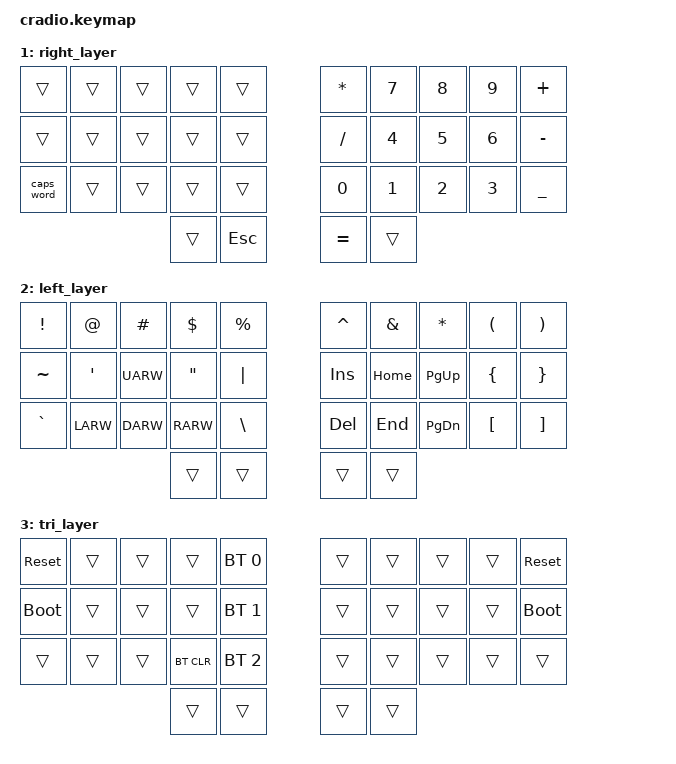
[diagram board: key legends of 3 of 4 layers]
// Copyright (c) 2022 The ZMK Contributors
// SPDX-License-Identifier: MIT

#include <behaviors.dtsi>
#include <dt-bindings/zmk/keys.h>
#include <dt-bindings/zmk/bt.h>

// Home row mods macro
#define HRML(k1,k2,k3,k4) &ht LSHFT k1  &ht LCTRL k2  &ht LALT k3  &ht LGUI k4
#define HRMR(k1,k2,k3,k4) &ht RGUI k1  &ht RALT k2  &ht RCTRL k3  &ht RSHFT k4

#define default_layer 0
#define right_layer 1
#define left_layer 2
#define tri_layer 3

// Combo Funct
#define COMBO(NAME, BINDINGS, LAYERS, KEYPOS) \
    combo_##NAME { \
        timeout-ms = <50>; \
        bindings = <BINDINGS>; \
        key-positions = <KEYPOS>; \
        layers = <LAYERS>;  \
    };

/ {
    behaviors {
        ht: hold_tap {
            compatible = "zmk,behavior-hold-tap";
            #binding-cells = <2>;
            flavor = "tap-preferred";
            tapping-term-ms = <220>;
            quick-tap-ms = <150>;
            require-prior-idle-ms = <100>;
            bindings = <&kp>, <&kp>;
        };
    };
};

/{
   macros {
        theMacro: theMacro {
            label = "THEMACRO";
            compatible = "zmk,behavior-macro";
            #binding-cells = <0>;
            bindings
                = <&kp T &kp H &kp E>;
        };

        gitPush: gitPushMacro {
            label = "GITPUSHMACRO";
            compatible = "zmk,behavior-macro";
            #binding-cells = <0>;
            bindings
                = <&kp G &kp I &kp T &kp SPACE &kp P &kp U &kp S &kp H &kp ENTER>;
        };

        gitPull: gitPullMacro {
            label = "GITPULLMACRO";
            compatible = "zmk,behavior-macro";
            #binding-cells = <0>;
            bindings
                = <&kp G &kp I &kp T &kp SPACE &kp P &kp U &kp L &kp L &kp ENTER>;
        };

        gitAdd: gitAddMacro {
            label = "GITADDMACRO";
            compatible = "zmk,behavior-macro";
            #binding-cells = <0>;
            bindings
                = <&kp G &kp I &kp T &kp SPACE &kp A &kp D &kp D &kp SPACE &kp DOT &kp ENTER>;
        };

        gitCommit: gitCommitMacro {
            label = "GITCOMMITMACRO";
            compatible = "zmk,behavior-macro";
            #binding-cells = <0>;
            bindings
                = <&kp G &kp I &kp T &kp SPACE &kp C &kp O &kp M &kp M &kp I &kp T &kp SPACE &kp MINUS &kp M &kp SPACE &kp DQT>;
        };

        clear: clearMacro {
            label = "CLEARMACRO";
            compatible = "zmk,behavior-macro";
            #binding-cells = <0>;
            bindings
                = <&kp C &kp L &kp E &kp A &kp R &kp ENTER>;
        };
    };
};

/{
    conditional_layers {
        compatible = "zmk,conditional-layers";
        tri_layer {
            if-layers = <1 2>;
            then-layer = <3>;
        };
    };
};

/*
/{
    combos{
        compatible = "zmk,combos";
        COMBO(easyThe, &theMacro, 0 1, 3 4)
        COMBO(pushCombo, &gitPush, 0 1, 14 16)
        COMBO(commitCombo, &gitCommit, 0 1, 14 15)
        COMBO(pullCombo, &gitPull, 0 1, 2 14)
        COMBO(addCombo, &gitAdd, 0 1, 3 14)
        COMBO(clearCombo, &clear, 0 1, 31 32)
        COMBO(wordDeleteW, &kp DELETEW, 0 1, 30 31)
        COMBO(wordDelete, &kp DELETE, 0, 30 31)
    };
};
*/

        //╭──────────┬──────────┬──────────┬──────────┬──────────╮   ╭──────────┬──────────┬──────────┬──────────┬──────────╮
        //│    0     │    1     │    2     │     3    │   4      │   │     5    │   6      │     7    │     8    │    9     │
        //├──────────┼──────────┼──────────┼──────────┼──────────┤   ├──────────┼──────────┼──────────┼──────────┼──────────┤
        //│    10    │    11    │    12    │   13     │   14     │   │   15     │    16    │    17    │    18    │    19    │
        //├──────────┼──────────┼──────────┼──────────┼──────────┤   ├──────────┼──────────┼──────────┼──────────┼──────────┤
        //│     20   │    21    │   22     │   23     │     24   │   │    25    │    26    │   27     │    28    │   29     │
        //╰──────────┴──────────┴──────────┼──────────┼──────────┤   ├──────────┼──────────┼──────────┴──────────┴──────────╯
        //                                 |    30    |     31   |   |    32    |    33    |
        //                                 ╰──────────┴──────────╯   ╰──────────┴──────────╯

/{
    keymap {
        compatible = "zmk,keymap";
        default_layer {
            bindings = <
        //╭──────────┬──────────┬──────────┬──────────┬──────────╮   ╭──────────┬──────────┬──────────┬──────────┬──────────╮
        //│  Q       │  W       │  E       │  R       │  T       │   │  Y       │  U       │  I       │  O       │  P       │
            &kp Q      &kp W      &kp E      &kp R      &kp T          &kp Y      &kp U      &kp I      &kp O      &kp P
        //├──────────┼──────────┼──────────┼──────────┼──────────┤   ├──────────┼──────────┼──────────┼──────────┼──────────┤
        //│  A       │  S       │  D       │  F       │  G       │   │  H       │  J       │  K       │  L       │ ; :      │
            HRML(A,        S,         D,         F)     &kp G          &kp H      HRMR(J,        K,         L,        SEMI)
        //├──────────┼──────────┼──────────┼──────────┼──────────┤   ├──────────┼──────────┼──────────┼──────────┼──────────┤
        //│  Z       │  X       │  C       │  V       │  B       │   │  N       │  M       │ , <      │ . >      │ / ?      │
            &kp Z      &kp X      &kp C      &kp V      &kp B          &kp N      &kp M      &kp COMMA  &kp DOT    &kp FSLH
        //╰──────────┴──────────┴──────────┼──────────┼──────────┤   ├──────────┼──────────┼──────────┴──────────┴──────────╯
                                            &lt 2 TAB   &kp SPACE     &kp ENTER  &lt 1 BSPC
        //                                 ╰──────────┴──────────╯   ╰──────────┴──────────╯
            >;
        };

        /*
        default_layer {
            bindings = <
        //╭──────────┬──────────┬──────────┬──────────┬──────────╮   ╭──────────┬──────────┬──────────┬──────────┬──────────╮
        //│  Q       │  W       │  E       │  R       │  T       │   │  Y       │  U       │  I       │  O       │  P       │
            &kp Q      &kp W      &kp E      &kp R      &kp T          &kp Y      &kp U      &kp I      &kp O      &kp P
        //├──────────┼──────────┼──────────┼──────────┼──────────┤   ├──────────┼──────────┼──────────┼──────────┼──────────┤
        //│  A       │  S       │  D       │  F       │  G       │   │  H       │  J       │  K       │  L       │ ; :      │
            HRML(A,        S,         D,         F)     &kp G          &kp H      HRMR(J,        K,         L,        SEMI)
        //├──────────┼──────────┼──────────┼──────────┼──────────┤   ├──────────┼──────────┼──────────┼──────────┼──────────┤
        //│  Z       │  X       │  C       │  V       │  B       │   │  N       │  M       │ , <      │ . >      │ / ?      │
            &kp Z      &kp X      &kp C      &kp V      &kp B          &kp N      &kp M      &kp COMMA  &kp DOT    &kp FSLH
        //╰──────────┴──────────┴──────────┼──────────┼──────────┤   ├──────────┼──────────┼──────────┴──────────┴──────────╯
                                            &lt 2 TAB   &kp SPACE     &kp ENTER  &lt 1 BSPC
        //                                 ╰──────────┴──────────╯   ╰──────────┴──────────╯
            >;
        };
        */

        right_layer {
            bindings = <
        //╭──────────┬──────────┬──────────┬──────────┬──────────╮   ╭──────────┬──────────┬──────────┬──────────┬──────────╮
        //│          │          │          │          │          │   │  *       │  7       │  8       │  9       │  +       │
            &trans     &trans     &trans     &trans     &trans         &kp ASTRK  &kp N7     &kp N8     &kp N9     &kp PLUS
        //├──────────┼──────────┼──────────┼──────────┼──────────┤   ├──────────┼──────────┼──────────┼──────────┼──────────┤
        //│          │          │          │          │          │   │  /       │  4       │  5       │  6       │  -       │
            &trans     &trans     &trans     &trans     &trans         &kp FSLH   &kp N4     &kp N5     &kp N6     &kp MINUS
        //├──────────┼──────────┼──────────┼──────────┼──────────┤   ├──────────┼──────────┼──────────┼──────────┼──────────┤
        //│ CAPS     │          │          │          │          │   │  0       │  1       │  2       │  3       │  _       │
           &caps_word  &trans     &trans     &trans     &trans         &kp N0     &kp N1     &kp N2     &kp N3     &kp UNDER
        //╰──────────┴──────────┴──────────┼──────────┼──────────┤   ├──────────┼──────────┼──────────┴──────────┴──────────╯
                                             &trans     &kp ESC        &kp EQUAL  &trans
        //                                 ╰──────────┴──────────╯   ╰──────────┴──────────╯
            >;
        };

        /*
        right_layer {
            bindings = <
        //╭──────────┬──────────┬──────────┬──────────┬──────────╮   ╭──────────┬──────────┬──────────┬──────────┬──────────╮
        //│ INSERT   │  1       │  2       │  3       │          │   │ HOME     │ PAGE DN  │ PAGE UP  │ END      │  "       │
            &kp INS    &kp N1     &kp N2     &kp N3     &trans         &kp HOME   &kp PG_DN  &kp PG_UP  &kp END    &kp DQT
        //├──────────┼──────────┼──────────┼──────────┼──────────┤   ├──────────┼──────────┼──────────┼──────────┼──────────┤
        //│ DELETE   │  4       │  5       │  6       │          │   │ LEFT     │ DOWN     │ UP       │ RIGHT    │  '       │
            &kp DEL    &kp N4     &kp N5     &kp N6     &trans         &kp LARW   &kp DARW   &kp UARW   &kp RARW   &kp SQT
        //├──────────┼──────────┼──────────┼──────────┼──────────┤   ├──────────┼──────────┼──────────┼──────────┼──────────┤
        //│ CAPS     │  7       │  8       │  9       │  0       │   │          │          │          │          │          │
           &caps_word  &kp N7     &kp N8     &kp N9     &kp N0         &trans     &trans     &trans     &trans     &trans
        //╰──────────┴──────────┴──────────┼──────────┼──────────┤   ├──────────┼──────────┼──────────┴──────────┴──────────╯
                                             &trans     &kp ESC        &trans     &trans
        //                                 ╰──────────┴──────────╯   ╰──────────┴──────────╯
            >;
        };
        */

        left_layer {
            bindings = <
        //╭──────────┬──────────┬──────────┬──────────┬──────────╮   ╭──────────┬──────────┬──────────┬──────────┬──────────╮
        //│  !       │  @       │  #       │  $       │  %       │   │  ^       │  &       │  *       │  (       │  )       │
            &kp EXCL   &kp AT     &kp HASH   &kp DLLR   &kp PRCNT      &kp CARET  &kp AMPS   &kp ASTRK  &kp LPAR   &kp RPAR
        //├──────────┼──────────┼──────────┼──────────┼──────────┤   ├──────────┼──────────┼──────────┼──────────┼──────────┤
        //│  ~       │  '       │ UP       │  "       │  |       │   │ INSERT   │ HOME     │ PAGE UP  │  {       │  }       │
            &kp TILDE  &kp SQT    &kp UARW   &kp DQT    &kp PIPE       &kp INS    &kp HOME   &kp PG_UP  &kp LBRC   &kp RBRC
        //├──────────┼──────────┼──────────┼──────────┼──────────┤   ├──────────┼──────────┼──────────┼──────────┼──────────┤
        //│  `       │ LEFT     │ DOWN     │ RIGHT    │  \       │   │ DELETE   │ END      │ PAGE DN  │  [       │  ]       │
            &kp GRAVE  &kp LARW   &kp DARW   &kp RARW   &kp BSLH       &kp DEL    &kp END    &kp PG_DN  &kp LBKT   &kp RBKT
        //╰──────────┴──────────┴──────────┼──────────┼──────────┤   ├──────────┼──────────┼──────────┴──────────┴──────────╯
                                             &trans     &trans         &trans     &trans
        //                                 ╰──────────┴──────────╯   ╰──────────┴──────────╯
            >;
        };

        /*
        left_layer {
            bindings = <
        //╭──────────┬──────────┬──────────┬──────────┬──────────╮   ╭──────────┬──────────┬──────────┬──────────┬──────────╮
        //│          │  [       │  {       │  }       │          │   │  ^       │  (       │  )       │  ]       │  ~       │
            &trans     &kp LBKT   &kp LBRC   &kp RBRC   &trans         &kp CARET  &kp LPAR   &kp RPAR   &kp RBKT   &kp TILDE
        //├──────────┼──────────┼──────────┼──────────┼──────────┤   ├──────────┼──────────┼──────────┼──────────┼──────────┤
        //│  !       │  @       │  #       │  $       │  %       │   │  *       │  -       │  =       │  \       │  `       │
            &kp EXCL   &kp AT     &kp HASH   &kp DLLR   &kp PRCNT      &kp ASTRK  &kp MINUS  &kp EQUAL  &kp BSLH   &kp GRAVE
        //├──────────┼──────────┼──────────┼──────────┼──────────┤   ├──────────┼──────────┼──────────┼──────────┼──────────┤
        //│          │          │          │          │          │   │  &       │  _       │  +       │  │       │          │
            &trans     &trans     &trans     &trans     &trans         &kp AMPS   &kp UNDER  &kp PLUS   &kp PIPE   &trans
        //╰──────────┴──────────┴──────────┼──────────┼──────────┤   ├──────────┼──────────┼──────────┴──────────┴──────────╯
                                             &trans     &trans         &trans     &trans
        //                                 ╰──────────┴──────────╯   ╰──────────┴──────────╯
            >;
        };
        */

        tri_layer {
            bindings = <
        //╭──────────┬──────────┬──────────┬──────────┬──────────╮   ╭──────────┬──────────┬──────────┬──────────┬──────────╮
        //│ RESET    │          │          │          │PROFILE 0 │   │          │          │          │          │  RESET   │
           &sys_reset  &trans     &trans     &trans    &bt BT_SEL 0    &trans     &trans     &trans     &trans    &sys_reset
        //├──────────┼──────────┼──────────┼──────────┼──────────┤   ├──────────┼──────────┼──────────┼──────────┼──────────┤
        //│BOOTLOADER│          │          │          │PROFILE 1 │   │          │          │          │          │BOOTLOADER│
          &bootloader  &trans     &trans     &trans    &bt BT_SEL 1    &trans     &trans     &trans     &trans    &bootloader
        //├──────────┼──────────┼──────────┼──────────┼──────────┤   ├──────────┼──────────┼──────────┼──────────┼──────────┤
        //│          │          │          │ CLEAR BT │PROFILE 2 │   │          │          │          │          │          │
            &trans     &trans     &trans    &bt BT_CLR &bt BT_SEL 2    &trans     &trans     &trans     &trans     &trans
        //╰──────────┴──────────┴──────────┼──────────┼──────────┤   ├──────────┼──────────┼──────────┴──────────┴──────────╯
                                             &trans     &trans         &trans     &trans
        //                                 ╰──────────┴──────────╯   ╰──────────┴──────────╯
            >;
        };

        /*
        tri_layer {
            bindings = <
        //╭──────────┬──────────┬──────────┬──────────┬──────────╮   ╭──────────┬──────────┬──────────┬──────────┬──────────╮
        //│ RESET    │          │          │          │PROFILE 0 │   │          │          │          │          │  RESET   │
           &sys_reset  &trans     &trans     &trans    &bt BT_SEL 0    &trans     &trans     &trans     &trans    &sys_reset
        //├──────────┼──────────┼──────────┼──────────┼──────────┤   ├──────────┼──────────┼──────────┼──────────┼──────────┤
        //│BOOTLOADER│          │          │          │PROFILE 1 │   │          │          │          │          │BOOTLOADER│
          &bootloader  &trans     &trans     &trans    &bt BT_SEL 1    &trans     &trans     &trans     &trans    &bootloader
        //├──────────┼──────────┼──────────┼──────────┼──────────┤   ├──────────┼──────────┼──────────┼──────────┼──────────┤
        //│          │          │          │ CLEAR BT │PROFILE 2 │   │          │          │          │          │          │
            &trans     &trans     &trans    &bt BT_CLR &bt BT_SEL 2    &trans     &trans     &trans     &trans     &trans
        //╰──────────┴──────────┴──────────┼──────────┼──────────┤   ├──────────┼──────────┼──────────┴──────────┴──────────╯
                                             &trans     &trans         &trans     &trans
        //                                 ╰──────────┴──────────╯   ╰──────────┴──────────╯
            >;
        };
        */
    };
};
